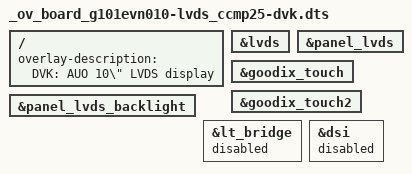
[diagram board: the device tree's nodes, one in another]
/*
 * Copyright 2024 Digi International Inc.
 *
 * Permission to use, copy, modify, and/or distribute this software for any
 * purpose with or without fee is hereby granted, provided that the above
 * copyright notice and this permission notice appear in all copies.
 * THE SOFTWARE IS PROVIDED "AS IS" AND THE AUTHOR DISCLAIMS ALL WARRANTIES
 * WITH REGARD TO THIS SOFTWARE INCLUDING ALL IMPLIED WARRANTIES OF
 * MERCHANTABILITY AND FITNESS. IN NO EVENT SHALL THE AUTHOR BE LIABLE FOR
 * ANY SPECIAL, DIRECT, INDIRECT, OR CONSEQUENTIAL DAMAGES OR ANY DAMAGES
 * WHATSOEVER RESULTING FROM LOSS OF USE, DATA OR PROFITS, WHETHER IN AN
 * ACTION OF CONTRACT, NEGLIGENCE OR OTHER TORTIOUS ACTION, ARISING OUT OF
 * OR IN CONNECTION WITH THE USE OR PERFORMANCE OF THIS SOFTWARE.
 */

#include <dt-bindings/rtc/rtc-stm32.h>

/dts-v1/;
/plugin/;

/ {
	fragment@0 {
		target-path = "/";
		__overlay__ {
			overlay-description = "DVK: AUO 10\" LVDS display";
		};
	};

	/* Enable backlight support */
	fragment@1 {
		target = <&panel_lvds_backlight>;
		__overlay__ {
			status = "okay";
		};
	};

	/* Enable LVDS */
	fragment@2 {
		target = <&lvds>;
		__overlay__ {
			status = "okay";
		};
	};

	/* Enable Panel LVDS */
	fragment@3 {
		target = <&panel_lvds>;
		__overlay__ {
			status = "okay";
		};
	};

	/* Enable Goodix touch panel */
	fragment@4 {
		target = <&goodix_touch>;
		__overlay__ {
			status = "okay";
		};
	};

	fragment@5 {
		target = <&goodix_touch2>;
		__overlay__ {
			status = "okay";
		};
	};

	/* Disable LT8912 */
	fragment@6 {
		target = <&lt_bridge>;
		__overlay__ {
			status = "disabled";
		};
	};

	/* Disable DSI */
	fragment@7 {
		target = <&dsi>;
		__overlay__ {
			status = "disabled";
		};
	};
};
